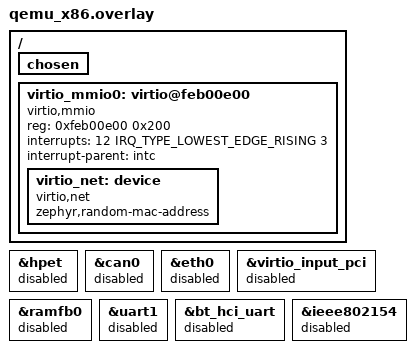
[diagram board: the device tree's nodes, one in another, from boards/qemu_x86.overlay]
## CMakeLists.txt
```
cmake_minimum_required(VERSION 3.20.0)
find_package(Zephyr REQUIRED HINTS $ENV{ZEPHYR_BASE})
project(vxprobe_zephyr)
target_sources(app PRIVATE src/main.c)
```

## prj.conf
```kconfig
# A UDP reflector for vxedge's qemu-microvm backend: echoes every datagram on :9800, as
# `vxprobe reflect` does, on a virtio-mmio NIC. IP and MAC arrive at run time.
CONFIG_SMP=n
CONFIG_MP_MAX_NUM_CPUS=1
CONFIG_MULTIBOOT_INFO=y
CONFIG_X86_MEMMAP=y
CONFIG_LOG=y
CONFIG_NETWORKING=y
CONFIG_NET_IPV4=y
CONFIG_NET_IPV6=n
CONFIG_NET_UDP=y
CONFIG_NET_SOCKETS=y
CONFIG_NET_L2_ETHERNET=y
CONFIG_NET_CONFIG_SETTINGS=n
CONFIG_NET_CONFIG_AUTO_INIT=n
CONFIG_NET_PKT_RX_COUNT=16
CONFIG_NET_PKT_TX_COUNT=16
CONFIG_NET_BUF_RX_COUNT=32
CONFIG_NET_BUF_TX_COUNT=32
CONFIG_VIRTIO=y
CONFIG_VIRTIO_MMIO=y
CONFIG_ETH_VIRTIO_NET=y
CONFIG_MAIN_STACK_SIZE=4096
CONFIG_DYNAMIC_INTERRUPTS=y
CONFIG_X86_DYNAMIC_IRQ_STUBS=8
# Zephyr's 32-bit PAE page tables set reserved bits in the PDPT entry, which KVM refuses with a
# triple fault on the CR0 write (QEMU's TCG accepts them). No MMU means no tables, and the loader's
# command line is addressable as it stands.
CONFIG_X86_MMU=n
```

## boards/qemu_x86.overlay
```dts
/* The QEMU microvm machine: no PCI, no HPET, one virtio-mmio transport per NIC at 0xfeb00000 +
 * 0x200 * n, wired to IOAPIC pin 5 + n. Everything the q35 board adds is switched off. */

/ {
	chosen {
		/delete-property/ zephyr,display;
		/delete-property/ zephyr,touch;
		/delete-property/ zephyr,canbus;
		/delete-property/ zephyr,bt-hci;
		/delete-property/ zephyr,bt-mon-uart;
		/delete-property/ zephyr,uart-pipe;
		/delete-property/ zephyr,ieee802154;
	};

	virtio_mmio0: virtio@feb00e00 {
		compatible = "virtio,mmio";
		reg = <0xfeb00e00 0x200>;
		interrupts = <12 IRQ_TYPE_LOWEST_EDGE_RISING 3>;
		interrupt-parent = <&intc>;
		status = "okay";

		virtio_net: device {
			compatible = "virtio,net";
			status = "okay";
			zephyr,random-mac-address;
		};
	};
};

&hpet { status = "disabled"; };
&can0 { status = "disabled"; };
&eth0 { status = "disabled"; };
&virtio_input_pci { status = "disabled"; };
&ramfb0 { status = "disabled"; };
&uart1 { status = "disabled"; };
&bt_hci_uart { status = "disabled"; };
&ieee802154 { status = "disabled"; };
```

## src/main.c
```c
/* A UDP reflector for vxedge's qemu-microvm backend.
 *
 * The zone-backend contract hands the guest its address on the kernel command line
 * (`vx.ip=<cidr>`), and QEMU passes that line to a Multiboot kernel after the kernel's own path.
 * The MAC is the one QEMU gave the NIC, read from the virtio device configuration, so vxedge's
 * per-node MAC reaches the wire. The payload echoes every datagram on :9800, as vxprobe does.
 */
#include <errno.h>
#include <stdlib.h>
#include <string.h>
#include <zephyr/arch/x86/multiboot.h>
#include <zephyr/drivers/virtio.h>
#include <zephyr/kernel.h>
#include <zephyr/logging/log.h>
#include <zephyr/net/net_if.h>
#include <zephyr/net/socket.h>

LOG_MODULE_REGISTER(vxprobe, LOG_LEVEL_INF);

#define PORT 9800

static const char *cmdline(void)
{
	if (!(multiboot_info.flags & MULTIBOOT_INFO_FLAGS_CMDLINE)) {
		return "";
	}
	/* No MMU: the loader's copy of the line is addressable as it stands. */
	return (const char *)(uintptr_t)multiboot_info.cmdline;
}

/* The value of `key=` in the command line, copied into out. */
static bool arg(const char *line, const char *key, char *out, size_t len)
{
	size_t kl = strlen(key);

	for (const char *p = line; *p; p++) {
		if ((p == line || p[-1] == ' ') && strncmp(p, key, kl) == 0 && p[kl] == '=') {
			size_t n = strcspn(p + kl + 1, " ");

			if (n >= len) {
				return false;
			}
			memcpy(out, p + kl + 1, n);
			out[n] = '\0';
			return true;
		}
	}
	return false;
}

static int set_ip(struct net_if *iface, char *cidr)
{
	char *slash = strchr(cidr, '/');
	struct in_addr addr, mask;
	int prefix = 24;

	if (slash) {
		*slash = '\0';
		prefix = atoi(slash + 1);
	}
	if (prefix < 1 || prefix > 32 || net_addr_pton(AF_INET, cidr, &addr) < 0) {
		return -EINVAL;
	}
	mask.s_addr = htonl(0xffffffffU << (32 - prefix));
	if (!net_if_ipv4_addr_add(iface, &addr, NET_ADDR_MANUAL, 0)) {
		return -ENOMEM;
	}
	net_if_ipv4_set_netmask_by_addr(iface, &addr, &mask);
	return 0;
}

/* The MAC QEMU gave the NIC lives in the first six bytes of the virtio net configuration. */
static void use_device_mac(struct net_if *iface)
{
	const struct device *vdev = DEVICE_DT_GET(DT_NODELABEL(virtio_mmio0));
	const uint8_t *cfg = virtio_get_device_specific_config(vdev);

	if (cfg == NULL) {
		LOG_WRN("no device configuration, keeping the driver's MAC");
		return;
	}
	net_if_down(iface);
	net_if_set_link_addr(iface, (uint8_t *)cfg, 6, NET_LINK_ETHERNET);
	net_if_up(iface);
}

int main(void)
{
	const char *line = cmdline();
	char cidr[32], node[48] = "unknown";
	struct net_if *iface = net_if_get_default();

	LOG_INF("cmdline: %s", line);
	if (iface == NULL) {
		LOG_ERR("no network interface");
		return 1;
	}
	use_device_mac(iface);
	arg(line, "vx.node", node, sizeof(node));
	if (!arg(line, "vx.ip", cidr, sizeof(cidr)) || set_ip(iface, cidr) != 0) {
		LOG_ERR("no usable vx.ip on the command line");
		return 1;
	}
	LOG_INF("vxparts guest up: node=%s, starting reflector :%d", node, PORT);

	int sock = zsock_socket(AF_INET, SOCK_DGRAM, IPPROTO_UDP);
	struct sockaddr_in bind_addr = {
		.sin_family = AF_INET,
		.sin_port = htons(PORT),
	};

	if (sock < 0 || zsock_bind(sock, (struct sockaddr *)&bind_addr, sizeof(bind_addr)) < 0) {
		LOG_ERR("cannot bind :%d (%d)", PORT, errno);
		return 1;
	}
	for (;;) {
		static uint8_t buf[1500];
		struct sockaddr_in peer;
		socklen_t plen = sizeof(peer);
		ssize_t n = zsock_recvfrom(sock, buf, sizeof(buf), 0, (struct sockaddr *)&peer, &plen);

		if (n > 0) {
			(void)zsock_sendto(sock, buf, n, 0, (struct sockaddr *)&peer, plen);
		}
	}
}
```
